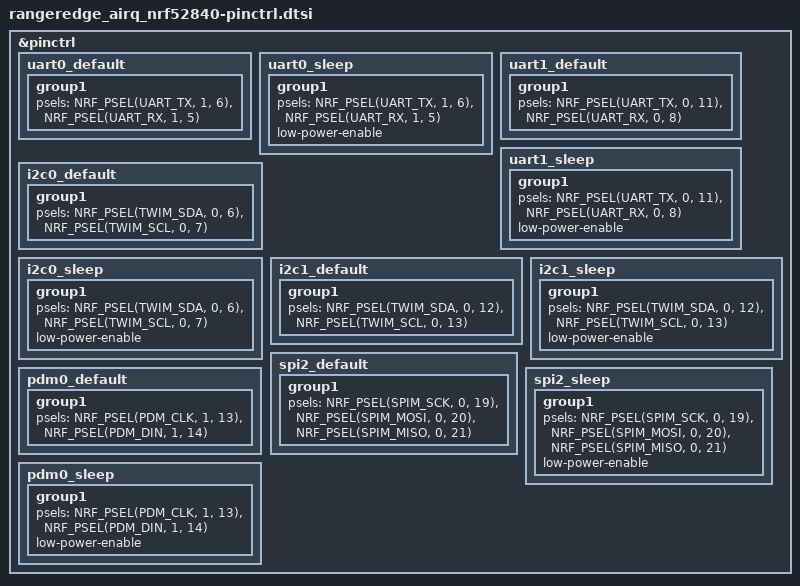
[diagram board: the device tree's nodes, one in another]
&pinctrl {

	uart0_default: uart0_default {
		group1 {
			psels = <NRF_PSEL(UART_TX, 1, 6)>,
					<NRF_PSEL(UART_RX, 1, 5)>;
		};
	};

	uart0_sleep: uart0_sleep {
		group1 {
			psels = <NRF_PSEL(UART_TX, 1, 6)>,
					<NRF_PSEL(UART_RX, 1, 5)>;
			low-power-enable;
		};
	};

	uart1_default: uart1_default {
		group1 {
			psels = <NRF_PSEL(UART_TX, 0, 11)>,
					<NRF_PSEL(UART_RX, 0, 8)>;
		};
	};

	uart1_sleep: uart1_sleep {
		group1 {
			psels = <NRF_PSEL(UART_TX, 0, 11)>,
					<NRF_PSEL(UART_RX, 0, 8)>;
			low-power-enable;
		};
	};
	i2c0_default: i2c0_default {
		group1 {
			psels = <NRF_PSEL(TWIM_SDA, 0, 6)>,
					<NRF_PSEL(TWIM_SCL, 0, 7)>;
		};
	};

	i2c0_sleep: i2c0_sleep {
		group1 {
			psels = <NRF_PSEL(TWIM_SDA, 0, 6)>,
					<NRF_PSEL(TWIM_SCL, 0, 7)>;
			low-power-enable;
		};
	};

    i2c1_default: i2c1_default {
		group1 {
			psels = <NRF_PSEL(TWIM_SDA, 0, 12)>,
					<NRF_PSEL(TWIM_SCL, 0, 13)>;
		};
	};

	i2c1_sleep: i2c1_sleep {
		group1 {
			psels = <NRF_PSEL(TWIM_SDA, 0, 12)>,
					<NRF_PSEL(TWIM_SCL, 0, 13)>;
			low-power-enable;
		};
	};

	spi2_default: spi2_default {
		group1 {
			psels = <NRF_PSEL(SPIM_SCK, 0, 19)>,
			        <NRF_PSEL(SPIM_MOSI, 0, 20)>,
			        <NRF_PSEL(SPIM_MISO, 0, 21)>;
		};
	};

	spi2_sleep: spi2_sleep {
		group1 {
			psels = <NRF_PSEL(SPIM_SCK, 0, 19)>,
			        <NRF_PSEL(SPIM_MOSI, 0, 20)>,
			        <NRF_PSEL(SPIM_MISO, 0, 21)>;
			low-power-enable;
		};
	};

	pdm0_default: pdm0_default {
		group1 {
			psels = <NRF_PSEL(PDM_CLK, 1, 13)>,
				<NRF_PSEL(PDM_DIN, 1, 14)>;
		};
	};

	pdm0_sleep: pdm0_sleep {
		group1 {
			psels = <NRF_PSEL(PDM_CLK, 1, 13)>,
				<NRF_PSEL(PDM_DIN, 1, 14)>;
			low-power-enable;
		};
	};
};
